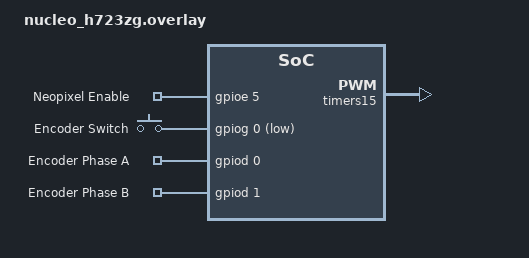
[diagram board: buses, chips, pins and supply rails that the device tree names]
#include <zephyr/dt-bindings/pwm/pwm.h>

/*-----          example of dts node:          -----*/
/{
    neopixel_enable: neopixel-enable {
        compatible = "gpio-keys";
        neopixel_en: neopixel_en {
            gpios = <&gpioe 5 GPIO_ACTIVE_HIGH>;
            label = "Neopixel Enable";
        };
    };

    rotary_encoder: rotary_encoder {
        compatible = "gpio-keys";
        encoder_s: encoder_switch {
            gpios = <&gpiog 0 (GPIO_PULL_UP | GPIO_ACTIVE_LOW)>;
            label = "Encoder Switch";
        };
        encoder_a: encoder_a {
            gpios = <&gpiod 0 (GPIO_PULL_UP | GPIO_ACTIVE_HIGH)>;
            label = "Encoder Phase A";
        };
        encoder_b: encoder_b {
            gpios = <&gpiod 1 (GPIO_PULL_UP | GPIO_ACTIVE_HIGH)>;
            label = "Encoder Phase B";
        };
    };
}

&timers15 {
    status = "okay";
    st,prescaler = <1>;

    pwm15: pwm {
        status = "okay";
        pinctrl-0 = <&tim15_ch1n_pe4>; /* TIM15_CH1N on PE4, it exists only negated */
        pinctrl-names = "default";
    };
};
